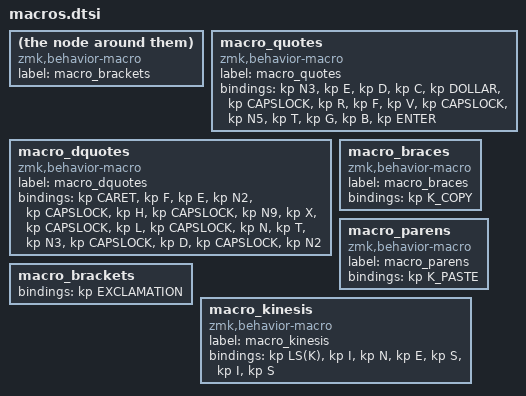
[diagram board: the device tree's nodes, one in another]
compatible = "zmk,behavior-macro";
label = "macro_brackets";
#binding-cells = <0>;
macro_quotes: macro_quotes{
compatible = "zmk,behavior-macro";
label = "macro_quotes";
#binding-cells = <0>;
bindings = <&kp N3>, <&kp E>, <&kp D>, <&kp C>, <&kp DOLLAR>, <&kp CAPSLOCK>, <&kp R>, <&kp F>, <&kp V>, <&kp CAPSLOCK>, <&kp N5>, <&kp T>, <&kp G>, <&kp B>, <&kp ENTER>;
};
macro_dquotes: macro_dquotes{
compatible = "zmk,behavior-macro";
label = "macro_dquotes";
#binding-cells = <0>;
bindings = <&kp CARET>, <&kp F>, <&kp E>, <&kp N2>, <&kp CAPSLOCK>, <&kp H>, <&kp CAPSLOCK>, <&kp N9>, <&kp X>, <&kp CAPSLOCK>, <&kp L>, <&kp CAPSLOCK>, <&kp N>, <&kp T>, <&kp N3>, <&kp CAPSLOCK>, <&kp D>, <&kp CAPSLOCK>, <&kp N2>;
};
macro_braces: macro_braces{
compatible = "zmk,behavior-macro";
label = "macro_braces";
#binding-cells = <0>;
bindings = <&kp K_COPY>;
};
macro_parens: macro_parens{
compatible = "zmk,behavior-macro";
label = "macro_parens";
#binding-cells = <0>;
bindings = <&kp K_PASTE>;
};
macro_brackets: macro_brackets{
bindings = <&kp EXCLAMATION>;
};	
	macro_kinesis: macro_kinesis{
	compatible = "zmk,behavior-macro";
label = "macro_kinesis";
#binding-cells = <0>;
bindings = <&kp LS(K)>, <&kp I>, <&kp N>, <&kp E>, <&kp S>, <&kp I>, <&kp S>;
};
